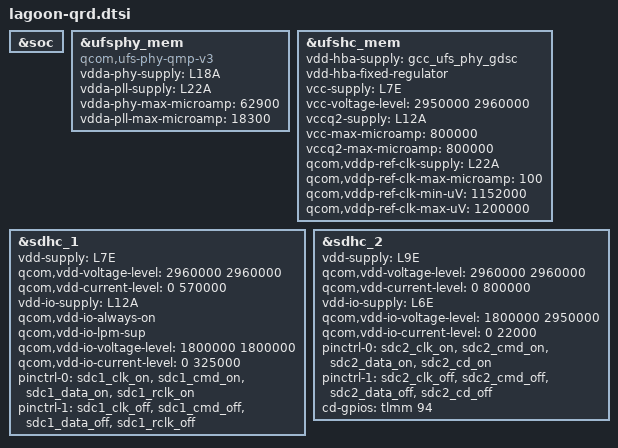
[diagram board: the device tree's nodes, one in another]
#include <dt-bindings/gpio/gpio.h>

&soc {

};

&ufsphy_mem {
	compatible = "qcom,ufs-phy-qmp-v3";

	vdda-phy-supply = <&L18A>;
	vdda-pll-supply = <&L22A>;
	vdda-phy-max-microamp = <62900>;
	vdda-pll-max-microamp = <18300>;

	status = "ok";
};

&ufshc_mem {
	vdd-hba-supply = <&gcc_ufs_phy_gdsc>;
	vdd-hba-fixed-regulator;
	vcc-supply = <&L7E>;
	vcc-voltage-level = <2950000 2960000>;
	vccq2-supply = <&L12A>;
	vcc-max-microamp = <800000>;
	vccq2-max-microamp = <800000>;

	qcom,vddp-ref-clk-supply = <&L22A>;
	qcom,vddp-ref-clk-max-microamp = <100>;
	qcom,vddp-ref-clk-min-uV = <1152000>;
	qcom,vddp-ref-clk-max-uV = <1200000>;
	status = "ok";
};

&sdhc_1 {
	vdd-supply = <&L7E>;
	qcom,vdd-voltage-level = <2960000 2960000>;
	qcom,vdd-current-level = <0 570000>;

	vdd-io-supply = <&L12A>;
	qcom,vdd-io-always-on;
	qcom,vdd-io-lpm-sup;
	qcom,vdd-io-voltage-level = <1800000 1800000>;
	qcom,vdd-io-current-level = <0 325000>;

	pinctrl-names = "active", "sleep";
	pinctrl-0 = <&sdc1_clk_on &sdc1_cmd_on &sdc1_data_on
					&sdc1_rclk_on>;
	pinctrl-1 = <&sdc1_clk_off &sdc1_cmd_off &sdc1_data_off
					&sdc1_rclk_off>;

	status = "ok";
};

&sdhc_2 {
	vdd-supply = <&L9E>;
	qcom,vdd-voltage-level = <2960000 2960000>;
	qcom,vdd-current-level = <0 800000>;

	vdd-io-supply = <&L6E>;
	qcom,vdd-io-voltage-level = <1800000 2950000>;
	qcom,vdd-io-current-level = <0 22000>;

	pinctrl-names = "active", "sleep";
	pinctrl-0 = <&sdc2_clk_on  &sdc2_cmd_on &sdc2_data_on &sdc2_cd_on>;
	pinctrl-1 = <&sdc2_clk_off &sdc2_cmd_off &sdc2_data_off &sdc2_cd_off>;

	cd-gpios = <&tlmm 94 GPIO_ACTIVE_HIGH>;

	status = "ok";
};
